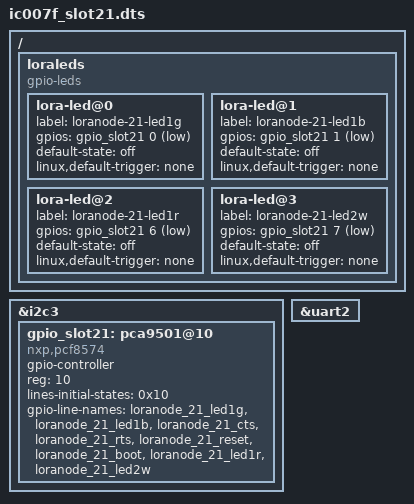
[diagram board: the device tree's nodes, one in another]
/dts-v1/;


/plugin/;

/ {
	fragment@0 {
		target = <&i2c3>;
		__overlay__ {
			#address-cells = <1>;
			#size-cells = <0>;
			gpio_slot21: pca9501@10 {
				compatible = "nxp,pcf8574";
				gpio-controller;
				#gpio-cells = <2>;
				reg = <10>;
				lines-initial-states = <0x10>;
                gpio-line-names ="loranode_21_led1g",
                "loranode_21_led1b",
                "loranode_21_cts",
                "loranode_21_rts",
                "loranode_21_reset",
                "loranode_21_boot",
                "loranode_21_led1r",
                "loranode_21_led2w";
                
			};
		};
	};

	fragment@3 {
		
		target = <&uart2>;
		__overlay__ {
			status = "okay";
		};

	};

	fragment@4 {
		target-path = "/";
		__overlay__ {
			loraleds {
				compatible = "gpio-leds";
				lora-led@0 {
					label = "loranode-21-led1g";
					gpios = <&gpio_slot21 0 1>;
					default-state = "off";
					linux,default-trigger = "none";
				};
				lora-led@1 {
					label = "loranode-21-led1b";
					gpios = <&gpio_slot21 1 1>;
					default-state = "off";
					linux,default-trigger = "none";
				};				
				lora-led@2 {
					label = "loranode-21-led1r";
					gpios = <&gpio_slot21 6 1>;
					default-state = "off";
					linux,default-trigger = "none";
				};
				lora-led@3 {
					label = "loranode-21-led2w";
					gpios = <&gpio_slot21 7 1>;
					default-state = "off";
					linux,default-trigger = "none";
				};
			};
		};
	};
};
